# Secure_IoT register map
Vendor: Mindgrove Technologies Private Limited; Series: Mindgrove Silicon; File version: 1.0.0
Mindgrove Silicon's Secure-IoT, based on IITM's Shakti Processor
CPU: VAJRA r1p9, little endian, MPU, FPU, double-precision FPU, I-cache, D-cache, 7 interrupt priority bits
Registers are 32-bit, read-write, reset 0x0 unless marked. A register's access mark holds for its fields unless they carry their own. Offsets are from the block's base; lines under a group give offsets from that group; [hi:lo] are bit positions; {n}, {i} and the like mark numbered series; 'fields as' and 'values as' point back to an identical list; <NAME> marks a mode.

## Memory map
0x00011300 UART0 size 0x20 — Universal asynchronous receiver and transmitter
0x00011400 UART1 size 0x20 — Universal asynchronous receiver and transmitter
0x00011500 UART2 size 0x20 — Universal asynchronous receiver and transmitter
0x00020000 SPI0 size 0x1C — SPI communication peripheral
0x00020100 SPI1 size 0x1C — SPI communication peripheral
0x00020200 SPI2 size 0x1C — SPI communication peripheral
0x00020300 SPI3 size 0x1C — SPI communication peripheral
0x00030000 PWM0 size 0x12 — Pulse-width modulation number 0
0x00030100 PWM1 size 0x12 — Pulse Width Modulator
0x00030200 PWM2 size 0x12 — Pulse Width Modulator
0x00030300 PWM3 size 0x12 — Pulse Width Modulator
0x00030400 PWM4 size 0x12 — Pulse Width Modulator
0x00030500 PWM5 size 0x12 — Pulse Width Modulator
0x00030600 PWM6 size 0x12 — Pulse Width Modulator
0x00030700 PWM7 size 0x12 — Pulse Width Modulator
0x00040000 QUADSPI0 size 0x30 — QuadSPI Interface 0
0x00040100 QUADSPI1 size 0x30 — QuadSPI Interface 1
0x00040200 GPIO size 0x34 — General purpose IO. 32 GPIOs are available
0x00040300 PINMUX0 size 0x20 — Pinmux which selects between GPIO and PWM.
0x00040400 WDT0 size 0x1C — Watchdog Timer
0x00044000 I2C0 size 0x40 — I2C communication peripheral
0x00044100 I2C1 size 0x40 — I2C communication peripheral
0x00044200 GPTIMER0 size 0x20 — General purpose timer
0x00044220 GPTIMER1 size 0x20 — General Purpose Timer
0x00044240 GPTIMER2 size 0x20 — General Purpose Timer
0x00044260 GPTIMER3 size 0x20 — General Purpose Timer
0x00060000 ITRACE size 0x24 — Instruction Trace
0x00060100 ITRACE_RAM size 0x100 — The RAM sink where all the trace packets are stored
0x02000000 CLINT0 size 0xBFFFF — Core Local Interrupt Controller
0x03000000 SHA256 size 0xD0 — SHA256 algorithm accelerator
0x04000000 AES size 0x78 — AES algorithm accelerator
0x05000000 RSA size 0xC8 — RSA crypto accelerator
0x0C000000 PLIC0 size 0x3FFFFFF — Platform Level Interrupt Controller

## Interrupts
{n+1} GPIO{n} (GPIO) (n=0..31)
33 PWM7
34 PWM6
35 PWM5
36 PWM4
37 PWM3
38 PWM2
39 PWM1
40 PWM0
41 GPTIMER0
42 GPTIMER1
43 GPTIMER2
44 GPTIMER3
45 I2C0
46 I2C1
47 UART0
48 UART1
49 UART2
50 QUADSPI1
51 QUADSPI1_READY (QUADSPI1)
52 QUADSPI0
53 QUADSPI0_READY (QUADSPI0)
54 SPI3
55 SPI2
56 SPI1
57 SPI0

## PWM0 — Pulse-width modulation number 0
Base 0x00030000
Same registers: PWM1 0x00030100, PWM2 0x00030200, PWM3 0x00030300, PWM4 0x00030400, PWM5 0x00030500, PWM6 0x00030600, PWM7 0x00030700
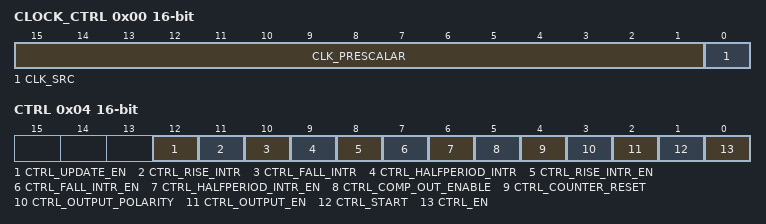
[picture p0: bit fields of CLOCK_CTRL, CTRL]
0x00 CLOCK_CTRL 16-bit — Clock prescalar register
  [15:1] CLK_PRESCALAR — PWM prescalar value
  [0] CLK_SRC — PWM clock select bit
0x04 CTRL 16-bit — PWM Control register
  [12] CTRL_UPDATE_EN — When this bit is set, the new values of period and duty cycle will be applied
  [11] CTRL_RISE_INTR — PWM rise interrupt bit
  [10] CTRL_FALL_INTR — PWM fall interrupt bit
  [9] CTRL_HALFPERIOD_INTR — PWM halfperiod interrupt bit
  [8] CTRL_RISE_INTR_EN — PWM rise interrupt enable
  [7] CTRL_FALL_INTR_EN — PWM fall interrupt enable
  [6] CTRL_HALFPERIOD_INTR_EN — PWM halfperiod interrupt enable
  [5] CTRL_COMP_OUT_ENABLE — PWM Complementary Output
  [4] CTRL_COUNTER_RESET — Resets the counter in PWM
  [3] CTRL_OUTPUT_POLARITY — PWM output polarity select flag
  [2] CTRL_OUTPUT_EN — PWM output enable flag
  [1] CTRL_START — PWM signal generation start flag
  [0] CTRL_EN — PWM controller enable flag
0x08 PERIOD — PWM period register
0x0C DUTY_CYCLE — PWM Duty_Cycle register
0x10 DEADBAND_DELAY 16-bit — PWM Deadband delay register
